# ESP32-S3 register map
Vendor: ESPRESSIF SYSTEMS (SHANGHAI) CO., LTD.; Series: ESP32 S-Series; File version: 22
CPU: Xtensa LX7 r0p0, little endian, no MPU, FPU, 0 interrupt priority bits
Address unit: 32 bits
Registers are 32-bit, read-write, reset 0x0 unless marked. A register's access mark holds for its fields unless they carry their own. Offsets are from the block's base; [hi:lo] are bit positions; {n}, {i} and the like mark numbered series.

## EFUSE — eFuse Controller
Base 0x60007000
0x00 PGM_DATA0 — Register 0 that stores data to be programmed.
  [31:0] PGM_DATA_0 — The content of the 0th 32-bit data to be programmed.
0x04 PGM_DATA1 — Register 1 that stores data to be programmed.
  [31:0] PGM_DATA_1 — The content of the 1st 32-bit data to be programmed.
0x08 PGM_DATA2 — Register 2 that stores data to be programmed.
  [31:0] PGM_DATA_2 — The content of the 2nd 32-bit data to be programmed.
0x0C PGM_DATA3 — Register 3 that stores data to be programmed.
  [31:0] PGM_DATA_3 — The content of the 3rd 32-bit data to be programmed.
{0x0+4i} PGM_DATA{i} (i=4..7) — Register {i} that stores data to be programmed.
  [31:0] PGM_DATA_{i} — The content of the {i}th 32-bit data to be programmed.
0x20 PGM_CHECK_VALUE0 — Register 0 that stores the RS code to be programmed.
  [31:0] PGM_RS_DATA_0 — The content of the 0th 32-bit RS code to be programmed.
0x24 PGM_CHECK_VALUE1 — Register 1 that stores the RS code to be programmed.
  [31:0] PGM_RS_DATA_1 — The content of the 1st 32-bit RS code to be programmed.
0x28 PGM_CHECK_VALUE2 — Register 2 that stores the RS code to be programmed.
  [31:0] PGM_RS_DATA_2 — The content of the 2nd 32-bit RS code to be programmed.
0x2C RD_WR_DIS ro — BLOCK0 data register 0.
  [31:0] WR_DIS — Disable programming of individual eFuses.
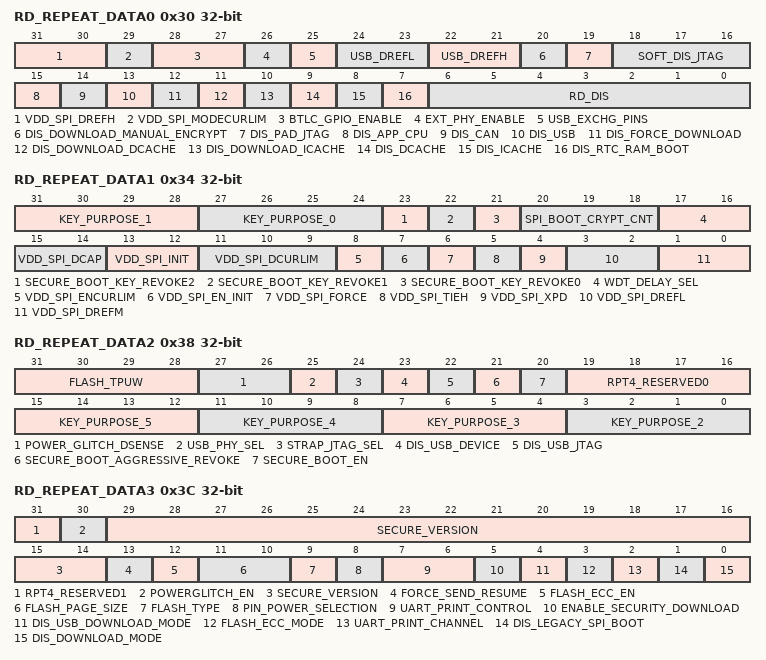
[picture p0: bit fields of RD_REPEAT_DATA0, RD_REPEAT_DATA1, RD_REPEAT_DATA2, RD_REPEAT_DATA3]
0x30 RD_REPEAT_DATA0 ro — BLOCK0 data register 1.
  [31:30] VDD_SPI_DREFH — SPI regulator high voltage reference.
  [29] VDD_SPI_MODECURLIM — SPI regulator switches current limit mode.
  [28:27] BTLC_GPIO_ENABLE — Bluetooth GPIO signal output security level control.
  [26] EXT_PHY_ENABLE — Set this bit to enable external PHY.
  [25] USB_EXCHG_PINS — Set this bit to exchange USB D+ and D- pins.
  [24:23] USB_DREFL — Controls single-end input threshold vrefl, 0.8 V to 1.04 V with step of 80 mV, stored in eFuse.
  [22:21] USB_DREFH — Controls single-end input threshold vrefh, 1.76 V to 2 V with step of 80 mV, stored in eFuse.
  [20] DIS_DOWNLOAD_MANUAL_ENCRYPT — Set this bit to disable flash encryption when in download boot modes.
  [19] DIS_PAD_JTAG — Set this bit to disable JTAG in the hard way. JTAG is disabled permanently.
  [18:16] SOFT_DIS_JTAG — Set these bits to disable JTAG in the soft way (odd number 1 means disable ). JTAG can be enabled in HMAC module.
  [15] DIS_APP_CPU — Disable app cpu.
  [14] DIS_CAN — Set this bit to disable CAN function.
  [13] DIS_USB — Set this bit to disable USB function.
  [12] DIS_FORCE_DOWNLOAD — Set this bit to disable the function that forces chip into download mode.
  [11] DIS_DOWNLOAD_DCACHE — Set this bit to disable Dcache in download mode ( boot_mode[3:0] is 0, 1, 2, 3, 6, 7).
  [10] DIS_DOWNLOAD_ICACHE — Set this bit to disable Icache in download mode (boot_mode[3:0] is 0, 1, 2, 3, 6, 7).
  [9] DIS_DCACHE — Set this bit to disable Dcache.
  [8] DIS_ICACHE — Set this bit to disable Icache.
  [7] DIS_RTC_RAM_BOOT — Set this bit to disable boot from RTC RAM.
  [6:0] RD_DIS — Set this bit to disable reading from BlOCK4-10.
0x34 RD_REPEAT_DATA1 ro — BLOCK0 data register 2.
  [31:28] KEY_PURPOSE_1 — Purpose of Key1.
  [27:24] KEY_PURPOSE_0 — Purpose of Key0.
  [23] SECURE_BOOT_KEY_REVOKE2 — Set this bit to enable revoking third secure boot key.
  [22] SECURE_BOOT_KEY_REVOKE1 — Set this bit to enable revoking second secure boot key.
  [21] SECURE_BOOT_KEY_REVOKE0 — Set this bit to enable revoking first secure boot key.
  [20:18] SPI_BOOT_CRYPT_CNT — Set this bit to enable SPI boot encrypt/decrypt. Odd number of 1: enable. even number of 1: disable.
  [17:16] WDT_DELAY_SEL — Selects RTC watchdog timeout threshold, in unit of slow clock cycle. 0: 40000. 1: 80000. 2: 160000. 3:320000.
  [15:14] VDD_SPI_DCAP — Prevents SPI regulator from overshoot.
  [13:12] VDD_SPI_INIT — Adds resistor from LDO output to ground. 0: no resistance 1: 6 K 2: 4 K 3: 2 K.
  [11:9] VDD_SPI_DCURLIM — Tunes the current limit threshold of SPI regulator when tieh=0, about 800 mA/(8+d).
  [8] VDD_SPI_ENCURLIM — Set SPI regulator to 1 to enable output current limit.
  [7] VDD_SPI_EN_INIT — Set SPI regulator to 0 to configure init[1:0]=0.
  [6] VDD_SPI_FORCE — Set this bit and force to use the configuration of eFuse to configure VDD_SPI.
  [5] VDD_SPI_TIEH — SPI regulator output is short connected to VDD3P3_RTC_IO.
  [4] VDD_SPI_XPD — SPI regulator power up signal.
  [3:2] VDD_SPI_DREFL — SPI regulator low voltage reference.
  [1:0] VDD_SPI_DREFM — SPI regulator medium voltage reference.
0x38 RD_REPEAT_DATA2 ro — BLOCK0 data register 3.
  [31:28] FLASH_TPUW — Configures flash waiting time after power-up, in unit of ms. If the value is less than 15, the waiting time is the configurable value. Otherwise, the waiting time is twice the configurable value.
  [27:26] POWER_GLITCH_DSENSE — Sample delay configuration of power glitch.
  [25] USB_PHY_SEL — This bit is used to switch internal PHY and external PHY for USB OTG and USB Device. 0: internal PHY is assigned to USB Device while external PHY is assigned to USB OTG. 1: internal PHY is assigned to USB OTG while external PHY is assigned to USB Device.
  [24] STRAP_JTAG_SEL — Set this bit to enable selection between usb_to_jtag and pad_to_jtag through strapping gpio10 when both reg_dis_usb_jtag and reg_dis_pad_jtag are equal to 0.
  [23] DIS_USB_DEVICE — Set this bit to disable usb device.
  [22] DIS_USB_JTAG — Set this bit to disable function of usb switch to jtag in module of usb device.
  [21] SECURE_BOOT_AGGRESSIVE_REVOKE — Set this bit to enable revoking aggressive secure boot.
  [20] SECURE_BOOT_EN — Set this bit to enable secure boot.
  [19:16] RPT4_RESERVED0 — Reserved (used for four backups method).
  [4n-5:4n-8] KEY_PURPOSE_{n} (n=2..5) — Purpose of Key{n}.
0x3C RD_REPEAT_DATA3 ro — BLOCK0 data register 4.
  [31] RPT4_RESERVED1 — Reserved (used for four backups method).
  [30] POWERGLITCH_EN — Set this bit to enable power glitch function.
  [29:14] SECURE_VERSION — Secure version (used by ESP-IDF anti-rollback feature).
  [13] FORCE_SEND_RESUME — Set this bit to force ROM code to send a resume command during SPI boot.
  [12] FLASH_ECC_EN — Set 1 to enable ECC for flash boot.
  [11:10] FLASH_PAGE_SIZE — Set Flash page size.
  [9] FLASH_TYPE — Set the maximum lines of SPI flash. 0: four lines. 1: eight lines.
  [8] PIN_POWER_SELECTION — GPIO33-GPIO37 power supply selection in ROM code. 0: VDD3P3_CPU. 1: VDD_SPI.
  [7:6] UART_PRINT_CONTROL — Set the default UARTboot message output mode. 00: Enabled. 01: Enabled when GPIO8 is low at reset. 10: Enabled when GPIO8 is high at reset. 11:disabled.
  [5] ENABLE_SECURITY_DOWNLOAD — Set this bit to enable secure UART download mode.
  [4] DIS_USB_DOWNLOAD_MODE — Set this bit to disable UART download mode through USB.
  [3] FLASH_ECC_MODE — Set ECC mode in ROM, 0: ROM would Enable Flash ECC 16to18 byte mode. 1:ROM would use 16to17 byte mode.
  [2] UART_PRINT_CHANNEL — Selectes the default UART print channel. 0: UART0. 1: UART1.
  [1] DIS_LEGACY_SPI_BOOT — Set this bit to disable Legacy SPI boot mode (boot_mode[3:0] = 4).
  [0] DIS_DOWNLOAD_MODE — Set this bit to disable download mode (boot_mode[3:0] = 0, 1, 2, 3, 6, 7).
0x40 RD_REPEAT_DATA4 ro — BLOCK0 data register 5.
  [23:0] RPT4_RESERVED2 — Reserved (used for four backups method).
0x44 RD_MAC_SPI_SYS_0 ro — BLOCK1 data register 0.
  [31:0] MAC_0 — Stores the low 32 bits of MAC address.
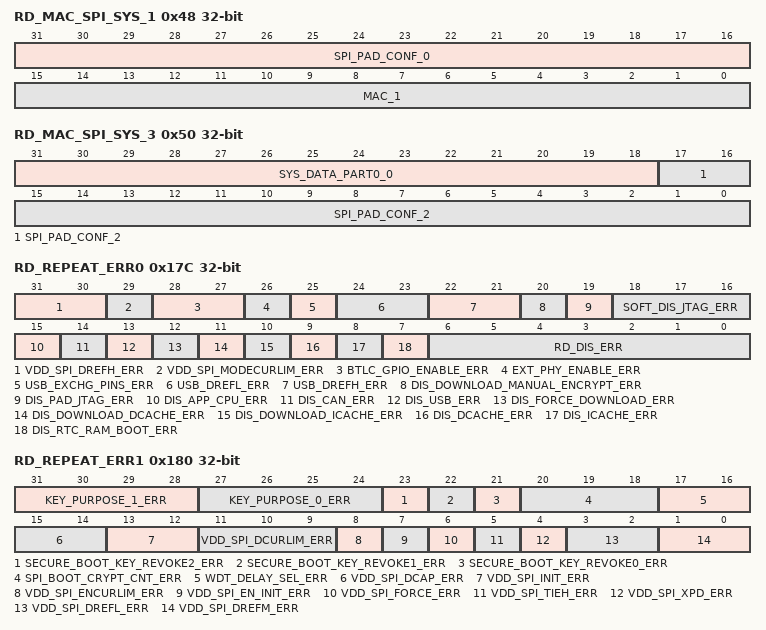
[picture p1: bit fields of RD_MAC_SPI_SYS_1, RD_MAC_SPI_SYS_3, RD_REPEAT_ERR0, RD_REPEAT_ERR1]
0x48 RD_MAC_SPI_SYS_1 ro — BLOCK1 data register 1.
  [31:16] SPI_PAD_CONF_0 — Stores the zeroth part of SPI_PAD_CONF.
  [15:0] MAC_1 — Stores the high 16 bits of MAC address.
0x4C RD_MAC_SPI_SYS_2 ro — BLOCK1 data register 2.
  [31:0] SPI_PAD_CONF_1 — Stores the first part of SPI_PAD_CONF.
0x50 RD_MAC_SPI_SYS_3 ro — BLOCK1 data register 3.
  [31:18] SYS_DATA_PART0_0 — Stores the fist 14 bits of the zeroth part of system data.
  [17:0] SPI_PAD_CONF_2 — Stores the second part of SPI_PAD_CONF.
0x54 RD_MAC_SPI_SYS_4 ro — BLOCK1 data register 4.
  [31:0] SYS_DATA_PART0_1 — Stores the fist 32 bits of the zeroth part of system data.
0x58 RD_MAC_SPI_SYS_5 ro — BLOCK1 data register 5.
  [31:0] SYS_DATA_PART0_2 — Stores the second 32 bits of the zeroth part of system data.
0x5C RD_SYS_PART1_DATA0 ro — Register 0 of BLOCK2 (system).
  [31:0] SYS_DATA_PART1_0 — Stores the zeroth 32 bits of the first part of system data.
0x60 RD_SYS_PART1_DATA1 ro — Register 1 of BLOCK2 (system).
  [31:0] SYS_DATA_PART1_1 — Stores the first 32 bits of the first part of system data.
0x64 RD_SYS_PART1_DATA2 ro — Register 2 of BLOCK2 (system).
  [31:0] SYS_DATA_PART1_2 — Stores the second 32 bits of the first part of system data.
0x68 RD_SYS_PART1_DATA3 ro — Register 3 of BLOCK2 (system).
  [31:0] SYS_DATA_PART1_3 — Stores the third 32 bits of the first part of system data.
0x6C RD_SYS_PART1_DATA4 ro — Register 4 of BLOCK2 (system).
  [31:0] SYS_DATA_PART1_4 — Stores the fourth 32 bits of the first part of system data.
0x70 RD_SYS_PART1_DATA5 ro — Register 5 of BLOCK2 (system).
  [31:0] SYS_DATA_PART1_5 — Stores the fifth 32 bits of the first part of system data.
0x74 RD_SYS_PART1_DATA6 ro — Register 6 of BLOCK2 (system).
  [31:0] SYS_DATA_PART1_6 — Stores the sixth 32 bits of the first part of system data.
0x78 RD_SYS_PART1_DATA7 ro — Register 7 of BLOCK2 (system).
  [31:0] SYS_DATA_PART1_7 — Stores the seventh 32 bits of the first part of system data.
0x7C RD_USR_DATA0 ro — Register 0 of BLOCK3 (user).
  [31:0] USR_DATA0 — Stores the zeroth 32 bits of BLOCK3 (user).
0x80 RD_USR_DATA1 ro — Register 1 of BLOCK3 (user).
  [31:0] USR_DATA1 — Stores the first 32 bits of BLOCK3 (user).
0x84 RD_USR_DATA2 ro — Register 2 of BLOCK3 (user).
  [31:0] USR_DATA2 — Stores the second 32 bits of BLOCK3 (user).
0x88 RD_USR_DATA3 ro — Register 3 of BLOCK3 (user).
  [31:0] USR_DATA3 — Stores the third 32 bits of BLOCK3 (user).
0x8C RD_USR_DATA4 ro — Register 4 of BLOCK3 (user).
  [31:0] USR_DATA4 — Stores the fourth 32 bits of BLOCK3 (user).
0x90 RD_USR_DATA5 ro — Register 5 of BLOCK3 (user).
  [31:0] USR_DATA5 — Stores the fifth 32 bits of BLOCK3 (user).
0x94 RD_USR_DATA6 ro — Register 6 of BLOCK3 (user).
  [31:0] USR_DATA6 — Stores the sixth 32 bits of BLOCK3 (user).
0x98 RD_USR_DATA7 ro — Register 7 of BLOCK3 (user).
  [31:0] USR_DATA7 — Stores the seventh 32 bits of BLOCK3 (user).
{0x9C+0x20*i} RD_KEY{i}_DATA0 ro (i=0..5) — Register 0 of BLOCK{i+4} (KEY{i}).
  [31:0] KEY{i}_DATA0 — Stores the zeroth 32 bits of KEY{i}.
{0xA0+0x20*i} RD_KEY{i}_DATA1 ro (i=0..5) — Register 1 of BLOCK{i+4} (KEY{i}).
  [31:0] KEY{i}_DATA1 — Stores the first 32 bits of KEY{i}.
{0xA4+0x20*i} RD_KEY{i}_DATA2 ro (i=0..5) — Register 2 of BLOCK{i+4} (KEY{i}).
  [31:0] KEY{i}_DATA2 — Stores the second 32 bits of KEY{i}.
{0xA8+0x20*i} RD_KEY{i}_DATA3 ro (i=0..5) — Register 3 of BLOCK{i+4} (KEY{i}).
  [31:0] KEY{i}_DATA3 — Stores the third 32 bits of KEY{i}.
{0xAC+0x20*i} RD_KEY{i}_DATA4 ro (i=0..5) — Register 4 of BLOCK{i+4} (KEY{i}).
  [31:0] KEY{i}_DATA4 — Stores the fourth 32 bits of KEY{i}.
{0xB0+0x20*i} RD_KEY{i}_DATA5 ro (i=0..5) — Register 5 of BLOCK{i+4} (KEY{i}).
  [31:0] KEY{i}_DATA5 — Stores the fifth 32 bits of KEY{i}.
{0xB4+0x20*i} RD_KEY{i}_DATA6 ro (i=0..5) — Register 6 of BLOCK{i+4} (KEY{i}).
  [31:0] KEY{i}_DATA6 — Stores the sixth 32 bits of KEY{i}.
{0xB8+0x20*i} RD_KEY{i}_DATA7 ro (i=0..5) — Register 7 of BLOCK{i+4} (KEY{i}).
  [31:0] KEY{i}_DATA7 — Stores the seventh 32 bits of KEY{i}.
0x15C RD_SYS_PART2_DATA0 ro — Register 0 of BLOCK10 (system).
  [31:0] SYS_DATA_PART2_0 — Stores the 0th 32 bits of the 2nd part of system data.
0x160 RD_SYS_PART2_DATA1 ro — Register 1 of BLOCK9 (KEY5).
  [31:0] SYS_DATA_PART2_1 — Stores the 1st 32 bits of the 2nd part of system data.
0x164 RD_SYS_PART2_DATA2 ro — Register 2 of BLOCK10 (system).
  [31:0] SYS_DATA_PART2_2 — Stores the 2nd 32 bits of the 2nd part of system data.
0x168 RD_SYS_PART2_DATA3 ro — Register 3 of BLOCK10 (system).
  [31:0] SYS_DATA_PART2_3 — Stores the 3rd 32 bits of the 2nd part of system data.
{0x15C+4i} RD_SYS_PART2_DATA{i} ro (i=4..7) — Register {i} of BLOCK10 (system).
  [31:0] SYS_DATA_PART2_{i} — Stores the {i}th 32 bits of the 2nd part of system data.
0x17C RD_REPEAT_ERR0 ro — Programming error record register 0 of BLOCK0.
  [31:30] VDD_SPI_DREFH_ERR — If any bits in this filed are 1, then it indicates a programming error.
  [29] VDD_SPI_MODECURLIM_ERR — If any bits in this filed are 1, then it indicates a programming error.
  [28:27] BTLC_GPIO_ENABLE_ERR — If any bits in this filed are 1, then it indicates a programming error.
  [26] EXT_PHY_ENABLE_ERR — If any bits in this filed are 1, then it indicates a programming error.
  [25] USB_EXCHG_PINS_ERR — If any bits in this filed are 1, then it indicates a programming error.
  [24:23] USB_DREFL_ERR — If any bits in this filed are 1, then it indicates a programming error.
  [22:21] USB_DREFH_ERR — If any bits in this filed are 1, then it indicates a programming error.
  [20] DIS_DOWNLOAD_MANUAL_ENCRYPT_ERR — If any bits in this filed are 1, then it indicates a programming error.
  [19] DIS_PAD_JTAG_ERR — If any bits in this filed are 1, then it indicates a programming error.
  [18:16] SOFT_DIS_JTAG_ERR — If any bits in this filed are 1, then it indicates a programming error.
  [15] DIS_APP_CPU_ERR — If any bits in this filed are 1, then it indicates a programming error.
  [14] DIS_CAN_ERR — If any bits in this filed are 1, then it indicates a programming error.
  [13] DIS_USB_ERR — If any bits in this filed are 1, then it indicates a programming error.
  [12] DIS_FORCE_DOWNLOAD_ERR — If any bits in this filed are 1, then it indicates a programming error.
  [11] DIS_DOWNLOAD_DCACHE_ERR — If any bits in this filed are 1, then it indicates a programming error.
  [10] DIS_DOWNLOAD_ICACHE_ERR — If any bits in this filed are 1, then it indicates a programming error.
  [9] DIS_DCACHE_ERR — If any bits in this filed are 1, then it indicates a programming error.
  [8] DIS_ICACHE_ERR — If any bits in this filed are 1, then it indicates a programming error.
  [7] DIS_RTC_RAM_BOOT_ERR — If any bits in this filed are 1, then it indicates a programming error.
  [6:0] RD_DIS_ERR — If any bits in this filed are 1, then it indicates a programming error.
0x180 RD_REPEAT_ERR1 ro — Programming error record register 1 of BLOCK0.
  [31:28] KEY_PURPOSE_1_ERR — If any bits in this filed are 1, then it indicates a programming error.
  [27:24] KEY_PURPOSE_0_ERR — If any bits in this filed are 1, then it indicates a programming error.
  [23] SECURE_BOOT_KEY_REVOKE2_ERR — If any bits in this filed are 1, then it indicates a programming error.
  [22] SECURE_BOOT_KEY_REVOKE1_ERR — If any bits in this filed are 1, then it indicates a programming error.
  [21] SECURE_BOOT_KEY_REVOKE0_ERR — If any bits in this filed are 1, then it indicates a programming error.
  [20:18] SPI_BOOT_CRYPT_CNT_ERR — If any bits in this filed are 1, then it indicates a programming error.
  [17:16] WDT_DELAY_SEL_ERR — If any bits in this filed are 1, then it indicates a programming error.
  [15:14] VDD_SPI_DCAP_ERR — If any bits in this filed are 1, then it indicates a programming error.
  [13:12] VDD_SPI_INIT_ERR — If any bits in this filed are 1, then it indicates a programming error.
  [11:9] VDD_SPI_DCURLIM_ERR — If any bits in this filed are 1, then it indicates a programming error.
  [8] VDD_SPI_ENCURLIM_ERR — If any bits in this filed are 1, then it indicates a programming error.
  [7] VDD_SPI_EN_INIT_ERR — If any bits in this filed are 1, then it indicates a programming error.
  [6] VDD_SPI_FORCE_ERR — If any bits in this filed are 1, then it indicates a programming error.
  [5] VDD_SPI_TIEH_ERR — If any bits in this filed are 1, then it indicates a programming error.
  [4] VDD_SPI_XPD_ERR — If any bits in this filed are 1, then it indicates a programming error.
  [3:2] VDD_SPI_DREFL_ERR — If any bits in this filed are 1, then it indicates a programming error.
  [1:0] VDD_SPI_DREFM_ERR — If any bits in this filed are 1, then it indicates a programming error.
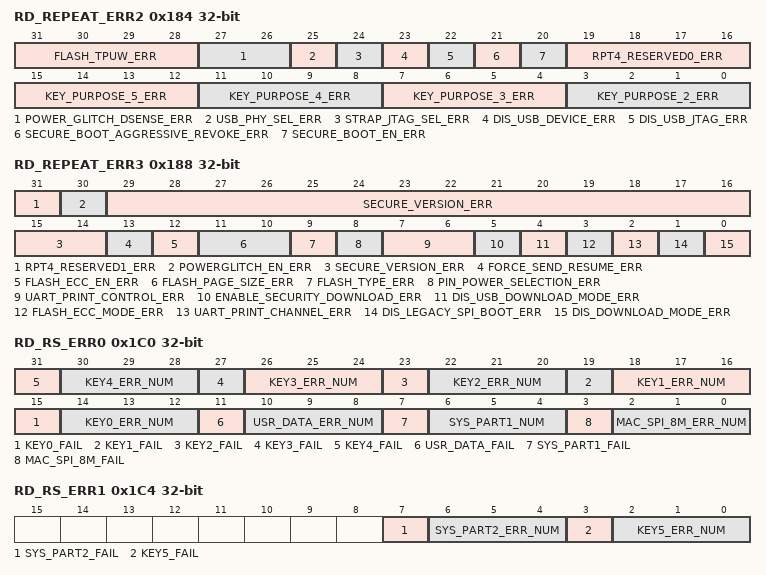
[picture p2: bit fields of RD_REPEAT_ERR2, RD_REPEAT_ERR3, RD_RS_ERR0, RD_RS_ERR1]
0x184 RD_REPEAT_ERR2 ro — Programming error record register 2 of BLOCK0.
  [31:28] FLASH_TPUW_ERR — If any bits in this filed are 1, then it indicates a programming error.
  [27:26] POWER_GLITCH_DSENSE_ERR — If any bits in this filed are 1, then it indicates a programming error.
  [25] USB_PHY_SEL_ERR — If any bits in this filed are 1, then it indicates a programming error.
  [24] STRAP_JTAG_SEL_ERR — If any bits in this filed are 1, then it indicates a programming error.
  [23] DIS_USB_DEVICE_ERR — If any bits in this filed are 1, then it indicates a programming error.
  [22] DIS_USB_JTAG_ERR — If any bits in this filed are 1, then it indicates a programming error.
  [21] SECURE_BOOT_AGGRESSIVE_REVOKE_ERR — If any bits in this filed are 1, then it indicates a programming error.
  [20] SECURE_BOOT_EN_ERR — If any bits in this filed are 1, then it indicates a programming error.
  [19:16] RPT4_RESERVED0_ERR — If any bits in this filed are 1, then it indicates a programming error.
  [4n-5:4n-8] KEY_PURPOSE_{n}_ERR (n=2..5) — If any bits in this filed are 1, then it indicates a programming error.
0x188 RD_REPEAT_ERR3 ro — Programming error record register 3 of BLOCK0.
  [31] RPT4_RESERVED1_ERR — Reserved.
  [30] POWERGLITCH_EN_ERR — If any bits in this filed are 1, then it indicates a programming error.
  [29:14] SECURE_VERSION_ERR — If any bits in this filed are 1, then it indicates a programming error.
  [13] FORCE_SEND_RESUME_ERR — If any bits in this filed are 1, then it indicates a programming error.
  [12] FLASH_ECC_EN_ERR — If any bits in this filed are 1, then it indicates a programming error.
  [11:10] FLASH_PAGE_SIZE_ERR — If any bits in this filed are 1, then it indicates a programming error.
  [9] FLASH_TYPE_ERR — If any bits in this filed are 1, then it indicates a programming error.
  [8] PIN_POWER_SELECTION_ERR — If any bits in this filed are 1, then it indicates a programming error.
  [7:6] UART_PRINT_CONTROL_ERR — If any bits in this filed are 1, then it indicates a programming error.
  [5] ENABLE_SECURITY_DOWNLOAD_ERR — If any bits in this filed are 1, then it indicates a programming error.
  [4] DIS_USB_DOWNLOAD_MODE_ERR — If any bits in this filed are 1, then it indicates a programming error.
  [3] FLASH_ECC_MODE_ERR — If any bits in this filed are 1, then it indicates a programming error.
  [2] UART_PRINT_CHANNEL_ERR — If any bits in this filed are 1, then it indicates a programming error.
  [1] DIS_LEGACY_SPI_BOOT_ERR — If any bits in this filed are 1, then it indicates a programming error.
  [0] DIS_DOWNLOAD_MODE_ERR — If any bits in this filed are 1, then it indicates a programming error.
0x190 RD_REPEAT_ERR4 ro — Programming error record register 4 of BLOCK0.
  [23:0] RPT4_RESERVED2_ERR — If any bits in this filed are 1, then it indicates a programming error.
0x1C0 RD_RS_ERR0 ro — Programming error record register 0 of BLOCK1-10.
  [4n+15] KEY{n}_FAIL (n=0..4) — 0: Means no failure and that the data of key{n} is reliable 1: Means that programming key{n} failed and the number of error bytes is over 6.
  [4n+14:4n+12] KEY{n}_ERR_NUM (n=0..4) — The value of this signal means the number of error bytes.
  [11] USR_DATA_FAIL — 0: Means no failure and that the user data is reliable 1: Means that programming user data failed and the number of error bytes is over 6.
  [10:8] USR_DATA_ERR_NUM — The value of this signal means the number of error bytes.
  [7] SYS_PART1_FAIL — 0: Means no failure and that the data of system part1 is reliable 1: Means that programming user data failed and the number of error bytes is over 6.
  [6:4] SYS_PART1_NUM — The value of this signal means the number of error bytes.
  [3] MAC_SPI_8M_FAIL — 0: Means no failure and that the data of MAC_SPI_8M is reliable 1: Means that programming user data failed and the number of error bytes is over 6.
  [2:0] MAC_SPI_8M_ERR_NUM — The value of this signal means the number of error bytes.
0x1C4 RD_RS_ERR1 ro — Programming error record register 1 of BLOCK1-10.
  [7] SYS_PART2_FAIL — 0: Means no failure and that the data of system part2 is reliable 1: Means that programming user data failed and the number of error bytes is over 6.
  [6:4] SYS_PART2_ERR_NUM — The value of this signal means the number of error bytes.
  [3] KEY5_FAIL — 0: Means no failure and that the data of KEY5 is reliable 1: Means that programming user data failed and the number of error bytes is over 6.
  [2:0] KEY5_ERR_NUM — The value of this signal means the number of error bytes.
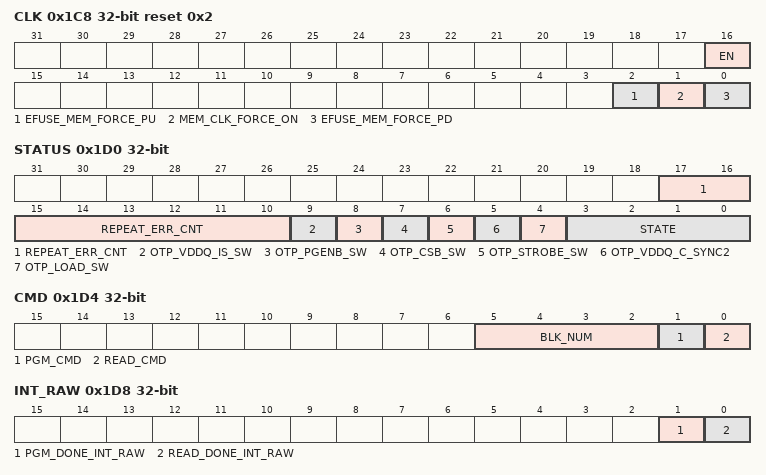
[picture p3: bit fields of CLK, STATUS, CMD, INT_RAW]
0x1C8 CLK reset 0x2 — eFuse clcok configuration register.
  [16] EN — Set this bit and force to enable clock signal of eFuse memory.
  [2] EFUSE_MEM_FORCE_PU — Set this bit to force eFuse SRAM into working mode.
  [1] MEM_CLK_FORCE_ON — Set this bit and force to activate clock signal of eFuse SRAM.
  [0] EFUSE_MEM_FORCE_PD — Set this bit to force eFuse SRAM into power-saving mode.
0x1CC CONF — eFuse operation mode configuraiton register
  [15:0] OP_CODE — 0x5A5A: Operate programming command 0x5AA5: Operate read command.
0x1D0 STATUS ro — eFuse status register.
  [17:10] REPEAT_ERR_CNT — Indicates the number of error bits during programming BLOCK0.
  [9] OTP_VDDQ_IS_SW — The value of OTP_VDDQ_IS_SW.
  [8] OTP_PGENB_SW — The value of OTP_PGENB_SW.
  [7] OTP_CSB_SW — The value of OTP_CSB_SW.
  [6] OTP_STROBE_SW — The value of OTP_STROBE_SW.
  [5] OTP_VDDQ_C_SYNC2 — The value of OTP_VDDQ_C_SYNC2.
  [4] OTP_LOAD_SW — The value of OTP_LOAD_SW.
  [3:0] STATE — Indicates the state of the eFuse state machine.
0x1D4 CMD — eFuse command register.
  [5:2] BLK_NUM — The serial number of the block to be programmed. Value 0-10 corresponds to block number 0-10, respectively.
  [1] PGM_CMD — Set this bit to send programming command.
  [0] READ_CMD — Set this bit to send read command.
0x1D8 INT_RAW — eFuse raw interrupt register.
  [1] PGM_DONE_INT_RAW — The raw bit signal for pgm_done interrupt.
  [0] READ_DONE_INT_RAW — The raw bit signal for read_done interrupt.
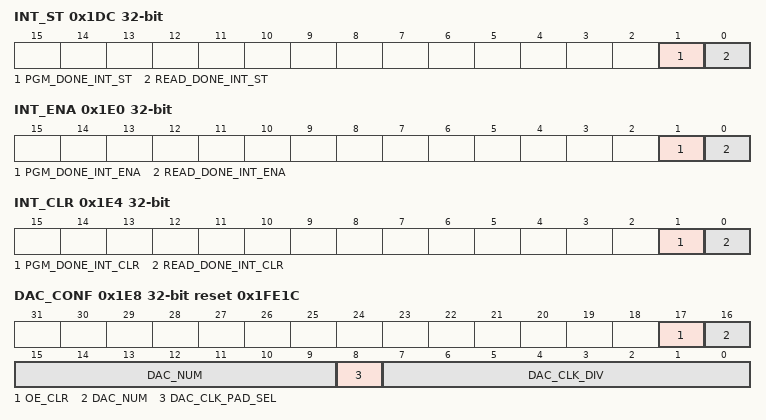
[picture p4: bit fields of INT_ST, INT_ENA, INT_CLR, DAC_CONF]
0x1DC INT_ST ro — eFuse interrupt status register.
  [1] PGM_DONE_INT_ST — The status signal for pgm_done interrupt.
  [0] READ_DONE_INT_ST — The status signal for read_done interrupt.
0x1E0 INT_ENA — eFuse interrupt enable register.
  [1] PGM_DONE_INT_ENA — The enable signal for pgm_done interrupt.
  [0] READ_DONE_INT_ENA — The enable signal for read_done interrupt.
0x1E4 INT_CLR wo — eFuse interrupt clear register.
  [1] PGM_DONE_INT_CLR — The clear signal for pgm_done interrupt.
  [0] READ_DONE_INT_CLR — The clear signal for read_done interrupt.
0x1E8 DAC_CONF reset 0x1FE1C — Controls the eFuse programming voltage.
  [17] OE_CLR — Reduces the power supply of the programming voltage.
  [16:9] DAC_NUM — Controls the rising period of the programming voltage.
  [8] DAC_CLK_PAD_SEL — Don't care.
  [7:0] DAC_CLK_DIV — Controls the division factor of the rising clock of the programming voltage.
0x1EC RD_TIM_CONF reset 0x12000000 — Configures read timing parameters.
  [31:24] READ_INIT_NUM — Configures the initial read time of eFuse.
0x1F4 WR_TIM_CONF1 reset 0x288000 — Configurarion register 1 of eFuse programming timing parameters.
  [23:8] PWR_ON_NUM — Configures the power up time for VDDQ.
0x1F8 WR_TIM_CONF2 reset 0x190 — Configurarion register 2 of eFuse programming timing parameters.
  [15:0] PWR_OFF_NUM — Configures the power outage time for VDDQ.
0x1FC DATE reset 0x2101290 — eFuse version register.
  [27:0] DATE — Stores eFuse version.
